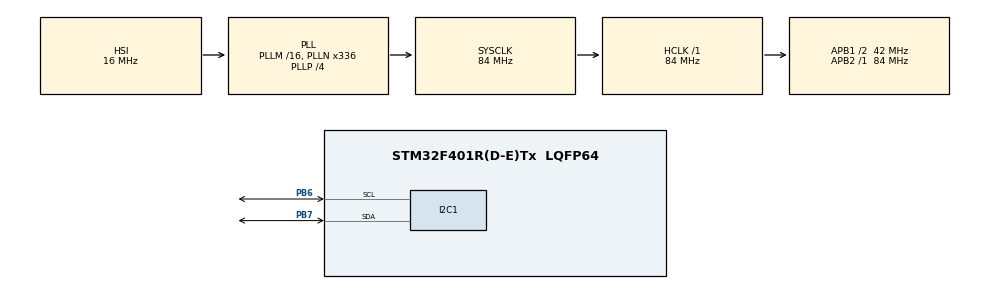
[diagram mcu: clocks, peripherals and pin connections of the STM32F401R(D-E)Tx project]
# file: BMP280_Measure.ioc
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Mcu.Family=STM32F4
RCC.CortexFreq_Value=84000000
RCC.APB1CLKDivider=RCC_HCLK_DIV2
RCC.SYSCLKSource=RCC_SYSCLKSOURCE_PLLCLK
ProjectManager.StackSize=0x400
ProjectManager.TargetToolchain=STM32CubeIDE
RCC.HCLKFreq_Value=84000000
RCC.APB2TimFreq_Value=84000000
PB6.Signal=I2C1_SCL
PB6.Mode=I2C
RCC.LSE_VALUE=32768
RCC.AHBFreq_Value=84000000
RCC.HSE_VALUE=8000000
board=NUCLEO-F401RE
RCC.VCOOutputFreq_Value=336000000
RCC.APB2Freq_Value=84000000
PB7.Signal=I2C1_SDA
Mcu.Name=STM32F401R(D-E)Tx
RCC.48MHZClocksFreq_Value=48000000
RCC.SYSCLKFreq_VALUE=84000000
Mcu.Package=LQFP64
PB7.Mode=I2C
ProjectManager.HeapSize=0x200
RCC.HSI_VALUE=16000000
RCC.PLLP=RCC_PLLP_DIV4
RCC.PLLQ=7
NVIC.PriorityGroup=NVIC_PRIORITYGROUP_0
RCC.PLLN=336
RCC.APB1TimFreq_Value=84000000
RCC.APB1Freq_Value=42000000

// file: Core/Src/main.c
/* USER CODE BEGIN Header */
/**
 ******************************************************************************
 * @file           : main.c
 * @brief          : Main program body
 ******************************************************************************
 * @attention
 *
 * <h2><center>&copy; Copyright (c) 2021 STMicroelectronics.
 * All rights reserved.</center></h2>
 *
 * This software component is licensed by ST under BSD 3-Clause license,
 * the "License"; You may not use this file except in compliance with the
 * License. You may obtain a copy of the License at:
 *                        opensource.org/licenses/BSD-3-Clause
 *
 ******************************************************************************
 */
/* USER CODE END Header */
#include "main.h"
#include "stdio.h"
#include "bmp280.h"
#include "stm32f4xx_hal.h"

/* USER CODE BEGIN Includes */
BMP280_HandleTypedef bmp280;

float pressure, temperature, humidity;

uint16_t size;
uint8_t Data[256];
uint8_t buffer[4];
/* USER CODE END Includes */

I2C_HandleTypeDef hi2c1;

void SystemClock_Config(void);
static void MX_GPIO_Init(void);
static void MX_I2C1_Init(void);

int main(void)
{

  /* MCU Configuration--------------------------------------------------------*/

  /* Reset of all peripherals, Initializes the Flash interface and the Systick. */
  HAL_Init();

  /* Configure the system clock */
  SystemClock_Config();

  /* Initialize all configured peripherals */
  MX_GPIO_Init();
  MX_I2C1_Init();
  /* USER CODE BEGIN 2 */
  bmp280_init_default_params(&bmp280.params);
  	bmp280.addr = BMP280_I2C_ADDRESS_0;
  	bmp280.i2c = &hi2c1;

  	while (!bmp280_init(&bmp280, &bmp280.params)) {
  			size = sprintf((char *)Data, "BMP280 initialization failed\n");
  			HAL_Delay(2000);
  		}
  		bool bme280p = bmp280.id == BME280_CHIP_ID;
  		size = sprintf((char *)Data, "BMP280: found %s\n", bme280p ? "BME280" : "BMP280");

  /* USER CODE END 2 */

  /* Infinite loop */
  /* USER CODE BEGIN WHILE */
	while (1)
	{

		HAL_Delay(100);
				while (!bmp280_read_float(&bmp280, &temperature, &pressure, &humidity)) {
					size = sprintf((char *)Data,
							"Temperature/pressure reading failed\n");
					HAL_Delay(2000);
				}

				size = sprintf((char *)Data,"Pressure: %.2f Pa, Temperature: %.2f C",
						pressure, temperature);

				if (bme280p) {
					size = sprintf((char *)Data,", Humidity: %.2f\n", humidity);

				}
				else {
					size = sprintf((char *)Data, "\n");
				}
				HAL_Delay(2000);

    /* USER CODE END WHILE */

	}
}

void SystemClock_Config(void)
{
  RCC_OscInitTypeDef RCC_OscInitStruct = {0};
  RCC_ClkInitTypeDef RCC_ClkInitStruct = {0};

  /** Configure the main internal regulator output voltage
  */
  __HAL_RCC_PWR_CLK_ENABLE();
  __HAL_PWR_VOLTAGESCALING_CONFIG(PWR_REGULATOR_VOLTAGE_SCALE2);
  /** Initializes the RCC Oscillators according to the specified parameters
  * in the RCC_OscInitTypeDef structure.
  */
  RCC_OscInitStruct.OscillatorType = RCC_OSCILLATORTYPE_HSI;
  RCC_OscInitStruct.HSIState = RCC_HSI_ON;
  RCC_OscInitStruct.HSICalibrationValue = RCC_HSICALIBRATION_DEFAULT;
  RCC_OscInitStruct.PLL.PLLState = RCC_PLL_ON;
  RCC_OscInitStruct.PLL.PLLSource = RCC_PLLSOURCE_HSI;
  RCC_OscInitStruct.PLL.PLLM = 16;
  RCC_OscInitStruct.PLL.PLLN = 336;
  RCC_OscInitStruct.PLL.PLLP = RCC_PLLP_DIV4;
  RCC_OscInitStruct.PLL.PLLQ = 7;
  if (HAL_RCC_OscConfig(&RCC_OscInitStruct) != HAL_OK)
  {
    Error_Handler();
  }
  /** Initializes the CPU, AHB and APB buses clocks
  */
  RCC_ClkInitStruct.ClockType = RCC_CLOCKTYPE_HCLK|RCC_CLOCKTYPE_SYSCLK
                              |RCC_CLOCKTYPE_PCLK1|RCC_CLOCKTYPE_PCLK2;
  RCC_ClkInitStruct.SYSCLKSource = RCC_SYSCLKSOURCE_PLLCLK;
  RCC_ClkInitStruct.AHBCLKDivider = RCC_SYSCLK_DIV1;
  RCC_ClkInitStruct.APB1CLKDivider = RCC_HCLK_DIV2;
  RCC_ClkInitStruct.APB2CLKDivider = RCC_HCLK_DIV1;

  if (HAL_RCC_ClockConfig(&RCC_ClkInitStruct, FLASH_LATENCY_2) != HAL_OK)
  {
    Error_Handler();
  }
}

static void MX_I2C1_Init(void)
{

  hi2c1.Instance = I2C1;
  hi2c1.Init.ClockSpeed = 100000;
  hi2c1.Init.DutyCycle = I2C_DUTYCYCLE_2;
  hi2c1.Init.OwnAddress1 = 0;
  hi2c1.Init.AddressingMode = I2C_ADDRESSINGMODE_7BIT;
  hi2c1.Init.DualAddressMode = I2C_DUALADDRESS_DISABLE;
  hi2c1.Init.OwnAddress2 = 0;
  hi2c1.Init.GeneralCallMode = I2C_GENERALCALL_DISABLE;
  hi2c1.Init.NoStretchMode = I2C_NOSTRETCH_DISABLE;
  if (HAL_I2C_Init(&hi2c1) != HAL_OK)
  {
    Error_Handler();
  }

}

static void MX_GPIO_Init(void)
{

  /* GPIO Ports Clock Enable */
  __HAL_RCC_GPIOB_CLK_ENABLE();

}

void Error_Handler(void)
{
	__disable_irq();
	while (1)
	{
	}
}

/************************ (C) COPYRIGHT STMicroelectronics *****END OF FILE****/
